# STM32U575 register map
File version: 1.3
CPU: CM33 r0p1, little endian, MPU, FPU, 4 interrupt priority bits
Registers are 32-bit, read-write, reset 0x0 unless marked. A register's access mark holds for its fields unless they carry their own. Offsets are from the block's base; [hi:lo] are bit positions.

## GTZC2_TZIC
Base 0x46023400
Same registers: SEC_GTZC2_TZIC 0x56023400
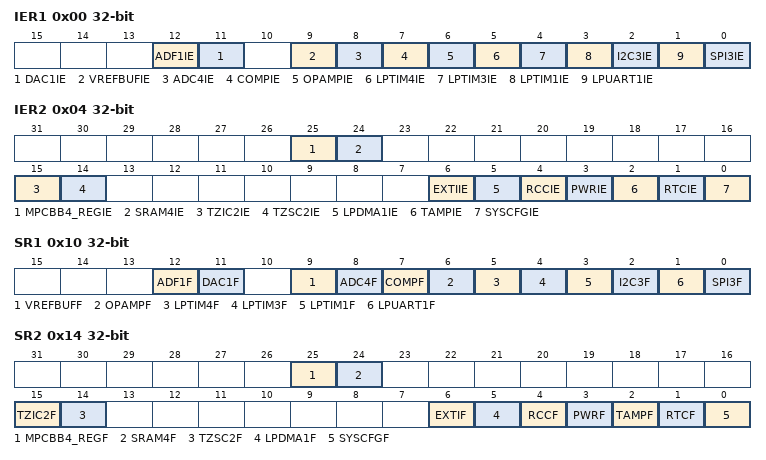
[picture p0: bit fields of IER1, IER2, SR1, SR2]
0x00 IER1 — TZIC interrupt enable register 1
  [12] ADF1IE — illegal access interrupt enable for ADF1
  [11] DAC1IE — illegal access interrupt enable for DAC1
  [9] VREFBUFIE — illegal access interrupt enable for VREFBUF
  [8] ADC4IE — illegal access interrupt enable for ADC4
  [7] COMPIE — illegal access interrupt enable for COMP
  [6] OPAMPIE — illegal access interrupt enable for OPAMP
  [5] LPTIM4IE — illegal access interrupt enable for LPTIM4
  [4] LPTIM3IE — illegal access interrupt enable for LPTIM3
  [3] LPTIM1IE — illegal access interrupt enable for LPTIM1
  [2] I2C3IE — illegal access interrupt enable for I2C3
  [1] LPUART1IE — illegal access interrupt enable for LPUART1
  [0] SPI3IE — illegal access interrupt enable for SPI3
0x04 IER2 — TZIC interrupt enable register 2
  [25] MPCBB4_REGIE — illegal access interrupt enable for MPCBB4 registers
  [24] SRAM4IE — illegal access interrupt enable for SRAM4
  [15] TZIC2IE — illegal access interrupt enable for GTZC2 TZIC registers
  [14] TZSC2IE — illegal access interrupt enable for GTZC2 TZSC registers
  [6] EXTIIE — illegal access interrupt enable for EXTI
  [5] LPDMA1IE — illegal access interrupt enable for LPDMA
  [4] RCCIE — illegal access interrupt enable for RCC
  [3] PWRIE — illegal access interrupt enable for PWR
  [2] TAMPIE — illegal access interrupt enable for TAMP
  [1] RTCIE — illegal access interrupt enable for RTC
  [0] SYSCFGIE — illegal access interrupt enable for SYSCFG
0x10 SR1 ro — TZIC status register 1
  [12] ADF1F — illegal access flag for ADF1
  [11] DAC1F — illegal access flag for DAC1
  [9] VREFBUFF — illegal access flag for VREFBUF
  [8] ADC4F — illegal access flag for ADC4
  [7] COMPF — illegal access flag for COMP
  [6] OPAMPF — illegal access flag for OPAMP
  [5] LPTIM4F — illegal access flag for LPTIM4
  [4] LPTIM3F — illegal access flag for LPTIM3
  [3] LPTIM1F — illegal access flag for LPTIM1
  [2] I2C3F — illegal access flag for I2C3
  [1] LPUART1F — illegal access flag for LPUART1
  [0] SPI3F — illegal access flag for SPI3
0x14 SR2 ro — TZIC status register 2
  [25] MPCBB4_REGF — illegal access flag for MPCBB4 registers
  [24] SRAM4F — illegal access flag for SRAM4
  [15] TZIC2F — illegal access flag for GTZC2 TZIC registers
  [14] TZSC2F — illegal access flag for GTZC2 TZSC registers
  [6] EXTIF — illegal access flag for EXTI
  [5] LPDMA1F — illegal access flag for LPDMA
  [4] RCCF — illegal access flag for RCC
  [3] PWRF — illegal access flag for PWRUSART1F
  [2] TAMPF — illegal access flag for TAMP
  [1] RTCF — illegal access flag for RTC
  [0] SYSCFGF — illegal access flag for SYSCFG
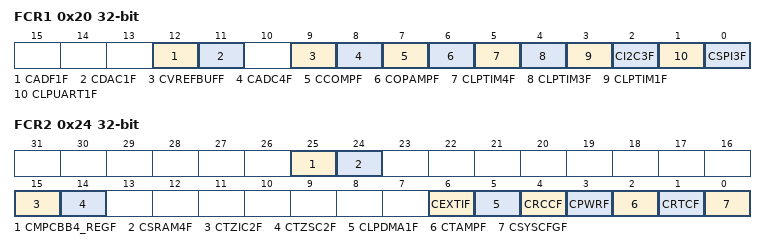
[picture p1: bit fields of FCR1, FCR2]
0x20 FCR1 wo — TZIC flag clear register 1
  [12] CADF1F — clear the illegal access flag for ADF1
  [11] CDAC1F — clear the illegal access flag for DAC1
  [9] CVREFBUFF — clear the illegal access flag for VREFBUF
  [8] CADC4F — clear the illegal access flag for ADC4
  [7] CCOMPF — clear the illegal access flag for COMP
  [6] COPAMPF — clear the illegal access flag for OPAMP
  [5] CLPTIM4F — clear the illegal access flag for LPTIM4
  [4] CLPTIM3F — clear the illegal access flag for LPTIM3
  [3] CLPTIM1F — clear the illegal access flag for LPTIM1
  [2] CI2C3F — clear the illegal access flag for I2C3
  [1] CLPUART1F — clear the illegal access flag for LPUART1
  [0] CSPI3F — clear the illegal access flag for SPI3
0x24 FCR2 wo — TZIC flag clear register 2
  [25] CMPCBB4_REGF — clear the illegal access flag for MPCBB4 registers
  [24] CSRAM4F — clear the illegal access flag for SRAM4
  [15] CTZIC2F — clear the illegal access flag for GTZC2 TZIC registers
  [14] CTZSC2F — clear the illegal access flag for GTZC2 TZSC registers
  [6] CEXTIF — clear the illegal access flag for EXTI
  [5] CLPDMA1F — clear the illegal access flag for LPDMA
  [4] CRCCF — clear the illegal access flag for RCC
  [3] CPWRF — clear the illegal access flag for PWR
  [2] CTAMPF — clear the illegal access flag for TAMP
  [1] CRTCF — clear the illegal access flag for RTC
  [0] CSYSCFGF — clear the illegal access flag for SYSCFG
